VERSION ""

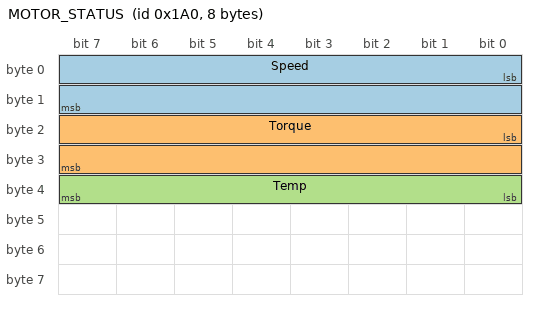
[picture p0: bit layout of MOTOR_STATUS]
BO_ 416 MOTOR_STATUS: 8 MOTOR
 SG_ Speed : 0|16@1+ (0.01,0) [0|500] "kph"
 SG_ Torque : 16|16@1- (0.1,0) [-500|500] "Nm"
 SG_ Temp : 32|8@1+ (1,-40) [0|200] "degC"

BO_ 256 HEARTBEAT: 8 MOTOR
 SG_ Counter : 0|8@1+ (1,0) [0|255] ""
 SG_ State : 8|8@1+ (1,0) [0|5] ""
